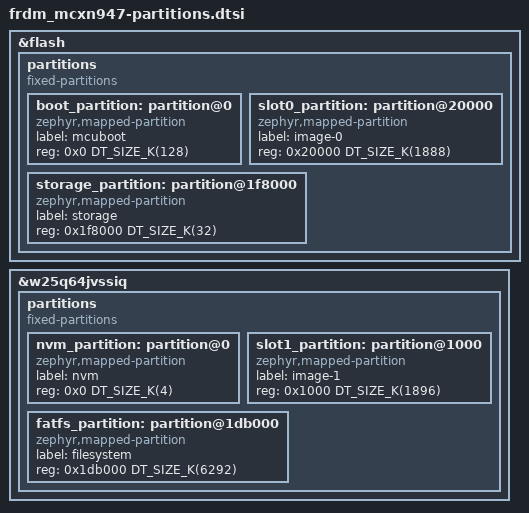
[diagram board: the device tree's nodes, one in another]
/* Partition layout for frdm_mcxn947: the flash memory map shared by the
 * bootloader and every application image. Generated by
 * tools/partition_layout.py; do not edit by hand -- re-run
 * `python3 tools/partition_layout.py --fix frdm_mcxn947` after changing
 * the upstream board geometry or tools/boards.toml.
 *
 * Board-specific overlay glue (delete-nodes, device enablement,
 * aliases/chosen) lives in dts/nxp/frdm_mcxn947.dtsi, which includes
 * this file.
 */

&flash {
	partitions {
		compatible = "fixed-partitions";
		#address-cells = <1>;
		#size-cells = <1>;
		ranges;

		boot_partition: partition@0 {
			compatible = "zephyr,mapped-partition";
			label = "mcuboot";
			reg = <0x0 DT_SIZE_K(128)>;
		};

		slot0_partition: partition@20000 {
			compatible = "zephyr,mapped-partition";
			label = "image-0";
			reg = <0x20000 DT_SIZE_K(1888)>;
		};

		storage_partition: partition@1f8000 {
			compatible = "zephyr,mapped-partition";
			label = "storage";
			reg = <0x1f8000 DT_SIZE_K(32)>;
		};
	};
};

&w25q64jvssiq {
	partitions {
		compatible = "fixed-partitions";
		#address-cells = <1>;
		#size-cells = <1>;
		ranges;

		nvm_partition: partition@0 {
			compatible = "zephyr,mapped-partition";
			label = "nvm";
			reg = <0x0 DT_SIZE_K(4)>;
		};

		slot1_partition: partition@1000 {
			compatible = "zephyr,mapped-partition";
			label = "image-1";
			reg = <0x1000 DT_SIZE_K(1896)>;
		};

		fatfs_partition: partition@1db000 {
			compatible = "zephyr,mapped-partition";
			label = "filesystem";
			reg = <0x1db000 DT_SIZE_K(6292)>;
		};
	};
};
